# STM32U5xx register map
File version: 1.3
Registers are 32-bit, read-write, reset 0x0 unless marked. A register's access mark holds for its fields unless they carry their own. Offsets are from the block's base; [hi:lo] are bit positions; {n}, {i} and the like mark numbered series.

## ADC2
Base 0x46021000
Same registers: SEC_ADC2 0x56021000
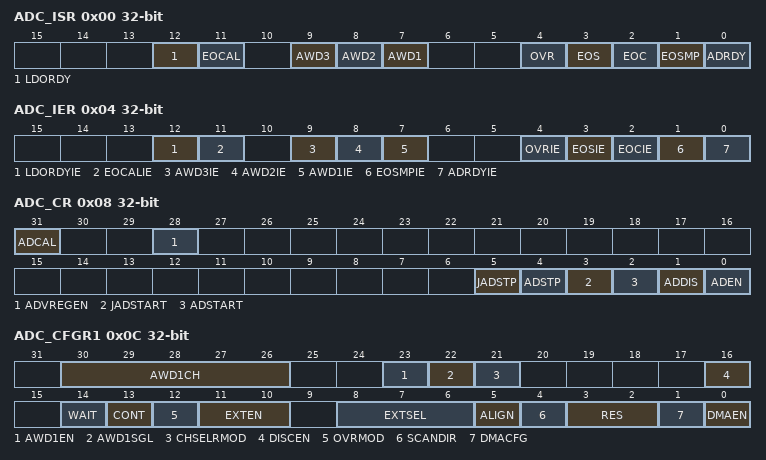
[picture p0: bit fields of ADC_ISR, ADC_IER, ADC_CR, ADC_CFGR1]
0x00 ADC_ISR — ADC interrupt and status register
  [12] LDORDY, [11] EOCAL, [9] AWD3, [8] AWD2, [7] AWD1, [4] OVR, [3] EOS, [2] EOC, [1] EOSMP, [0] ADRDY
0x04 ADC_IER — ADC interrupt enable register
  [12] LDORDYIE, [11] EOCALIE, [9] AWD3IE, [8] AWD2IE, [7] AWD1IE, [4] OVRIE, [3] EOSIE, [2] EOCIE, [1] EOSMPIE, [0] ADRDYIE
0x08 ADC_CR access per field — ADC control register
  [31] ADCAL ro, [28] ADVREGEN rw, [5] JADSTP ro, [4] ADSTP ro, [3] JADSTART ro, [2] ADSTART ro, [1] ADDIS ro, [0] ADEN ro
0x0C ADC_CFGR1 — ADC configuration register
  [30:26] AWD1CH, [23] AWD1EN, [22] AWD1SGL, [21] CHSELRMOD, [16] DISCEN, [14] WAIT, [13] CONT, [12] OVRMOD, [11:10] EXTEN, [8:6] EXTSEL, [5] ALIGN, [4] SCANDIR, [3:2] RES, [1] DMACFG, [0] DMAEN
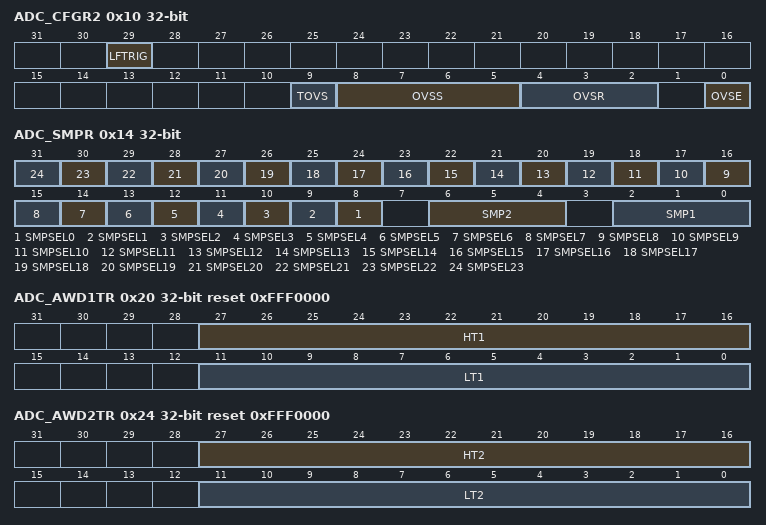
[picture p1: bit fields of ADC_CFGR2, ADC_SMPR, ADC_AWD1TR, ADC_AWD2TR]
0x10 ADC_CFGR2 — ADC configuration register 2
  [29] LFTRIG, [9] TOVS, [8:5] OVSS, [4:2] OVSR, [0] OVSE
0x14 ADC_SMPR — ADC sample time register
  [n+8] SMPSEL{n} (n=0..23), [6:4] SMP2, [2:0] SMP1
0x20 ADC_AWD1TR reset 0xFFF0000 — ADC watchdog threshold register
  [27:16] HT1, [11:0] LT1
0x24 ADC_AWD2TR reset 0xFFF0000 — ADC watchdog threshold register
  [27:16] HT2, [11:0] LT2
0x28 ADC_CHSELRMOD0 — ADC channel selection register [alternate]
  [23:0] CHSEL
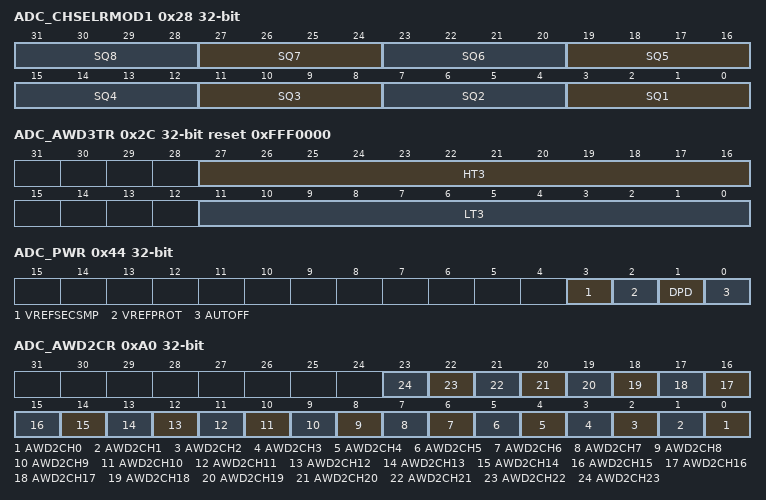
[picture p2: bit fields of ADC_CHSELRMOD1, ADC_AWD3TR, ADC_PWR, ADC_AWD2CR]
0x28 ADC_CHSELRMOD1 (alternate view of ADC_CHSELRMOD0) — ADC channel selection register [alternate]
  [4n-1:4n-4] SQ{n} (n=1..8)
0x2C ADC_AWD3TR reset 0xFFF0000 — ADC watchdog threshold register
  [27:16] HT3, [11:0] LT3
0x40 ADC_DR ro — ADC data register
  [15:0] DATA
0x44 ADC_PWR — ADC data register
  [3] VREFSECSMP, [2] VREFPROT, [1] DPD, [0] AUTOFF
0xA0 ADC_AWD2CR — ADC Analog Watchdog 2 Configuration register
  [n] AWD2CH{n} (n=0..23)
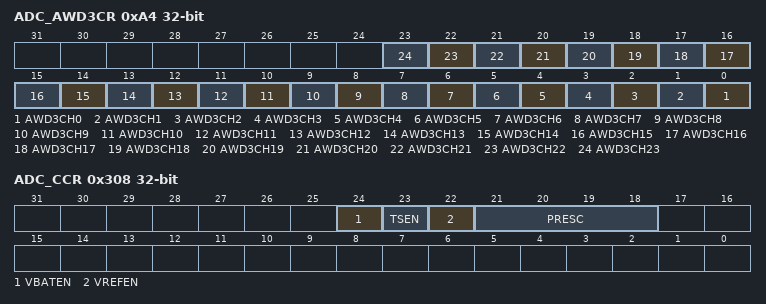
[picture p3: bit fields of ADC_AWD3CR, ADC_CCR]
0xA4 ADC_AWD3CR — ADC Analog Watchdog 3 Configuration register
  [n] AWD3CH{n} (n=0..23)
0xB4 ADC_CALFACT — ADC Calibration factor
  [6:0] CALFACT
0xD0 ADC_OR — ADC option register
  [0] CHN0SEL
0x308 ADC_CCR — ADC common configuration register
  [24] VBATEN, [23] TSEN, [22] VREFEN, [21:18] PRESC

## RNG — Random number generator
Base 0x420C0800
Same registers: SEC_RNG 0x520C0800
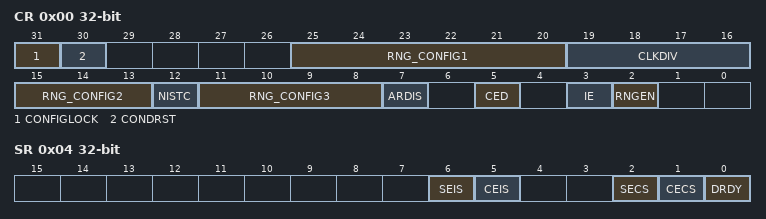
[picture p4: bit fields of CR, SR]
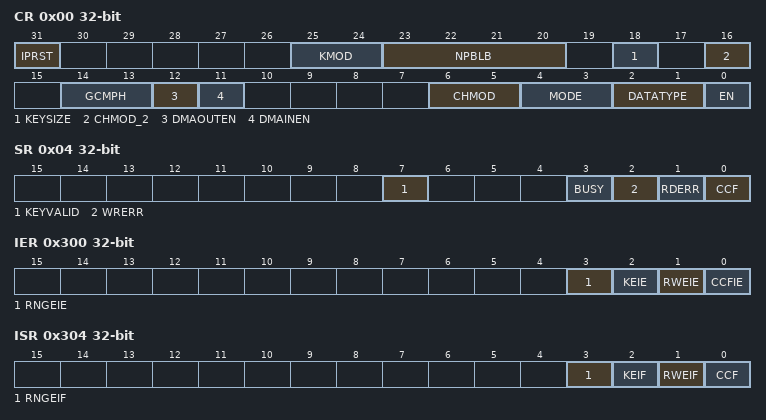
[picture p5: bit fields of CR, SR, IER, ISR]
0x00 CR — control register
  [31] CONFIGLOCK — RNG Config Lock
  [30] CONDRST — Conditioning soft reset
  [25:20] RNG_CONFIG1 — RNG configuration 1
  [19:16] CLKDIV — Clock divider factor
  [15:13] RNG_CONFIG2 — RNG configuration 2
  [12] NISTC — Non NIST compliant
  [11:8] RNG_CONFIG3 — RNG configuration 3
  [7] ARDIS — Auto reset disable
  [5] CED — Clock error detection
  [3] IE — Interrupt Enable
  [2] RNGEN — True random number generator enable
0x04 SR access per field — status register
  [6] SEIS rw — Seed error interrupt status
  [5] CEIS rw — Clock error interrupt status
  [2] SECS ro — Seed error current status
  [1] CECS ro — Clock error current status
  [0] DRDY ro — Data ready
0x08 DR ro — data register
  [31:0] RNDATA — Random data
0x10 HTCR reset 0x6274 — health test control register
  [31:0] HTCFG — health test configuration

## AES — Advanced encryption standard hardware accelerator
Base 0x420C0000
Same registers: SEC_AES 0x520C0000
0x00 CR — control register
  [31] IPRST
  [25:24] KMOD
  [23:20] NPBLB
  [18] KEYSIZE
  [16] CHMOD_2
  [14:13] GCMPH
  [12] DMAOUTEN — Enable DMA management of data output phase
  [11] DMAINEN — Enable DMA management of data input phase
  [6:5] CHMOD — AES chaining mode
  [4:3] MODE — AES operating mode
  [2:1] DATATYPE — Data type selection (for data in and data out to/from the cryptographic block)
  [0] EN — AES enable
0x04 SR ro — status register
  [7] KEYVALID — Key Valid flag
  [3] BUSY
  [2] WRERR — Write error flag
  [1] RDERR — Read error flag
  [0] CCF — Computation complete flag
0x08 DINR wo — data input register
  [31:0] DIN — Input data word
0x0C DOUTR ro — data output register
  [31:0] DOUT — Output data word
0x10 KEYR0 wo — key register 0
  [31:0] KEY — Cryptographic key, bits [31:0]
0x14 KEYR1 wo — key register 1
  [31:0] KEY — Cryptographic key, bits [63:32]
0x18 KEYR2 wo — key register 2
  [31:0] KEYR — Cryptographic key, bits [95:64]
0x1C KEYR3 wo — key register 3
  [31:0] AES_KEYR3 — Cryptographic key, bits [127:96]
{0x20+4i} IVR{i} (i=0..3) — initialization vector register {i}
  [31:0] IVI — Initialization vector input, bits [{32i+31}:{32i}]
{0x20+4i} KEYR{i} wo (i=4..7) — key register {i}
  [31:0] KEY — Cryptographic key, bits [{32i+31}:{32i}]
{0x40+4i} SUSP{i}R wo (i=0..7) — suspend registers
  [31:0] SUSP{i} — AES suspend
0x300 IER — interrupt enable register
  [3] RNGEIE — Key error interrupt flag
  [2] KEIE — Key error interrupt flag
  [1] RWEIE — Read or write error interrupt flag
  [0] CCFIE — Computation complete flag
0x304 ISR ro — interrupt status register
  [3] RNGEIF — Key error interrupt flag
  [2] KEIF — Key error interrupt flag
  [1] RWEIF — Read or write error interrupt flag
  [0] CCF — Computation complete flag
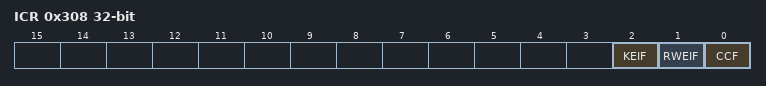
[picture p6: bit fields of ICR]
0x308 ICR wo — interrupt clear register
  [2] KEIF — Key error interrupt flag clear
  [1] RWEIF — Read or write error interrupt flag clear
  [0] CCF — Computation complete flag clear

## SAES — Secure AES coprocessor
Base 0x420C0C00
Same registers: SEC_SAES 0x520C0C00
Registers as AES (with AES read as SAES), without SUSP{n}R (n=0..7); these are added or differ:
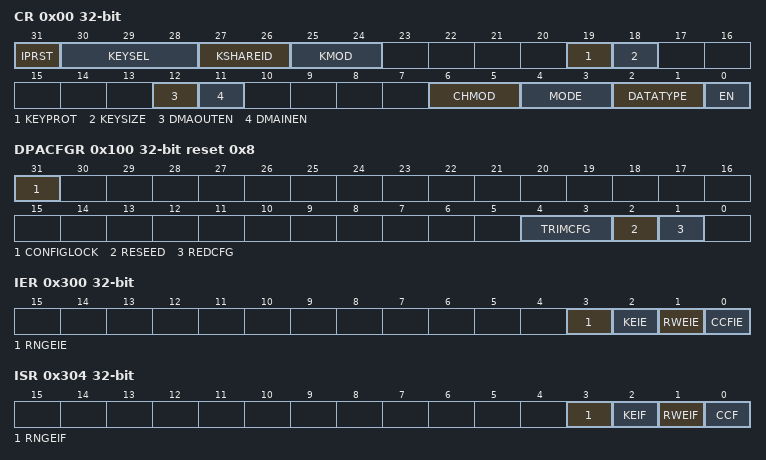
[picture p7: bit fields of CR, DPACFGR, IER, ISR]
0x00 CR — control register
  [31] IPRST
  [30:28] KEYSEL
  [27:26] KSHAREID
  [25:24] KMOD
  [19] KEYPROT
  [18] KEYSIZE
  [12] DMAOUTEN
  [11] DMAINEN
  [6:5] CHMOD
  [4:3] MODE
  [2:1] DATATYPE
  [0] EN — SAES enable
0x100 DPACFGR access per field reset 0x8 — configuration register
  [31] CONFIGLOCK ro, [4:3] TRIMCFG rw, [2] RESEED rw, [1] REDCFG rw
0x300 IER — interrupt enable register
  [3] RNGEIE
  [2] KEIE — Key error interrupt enable
  [1] RWEIE — Read or write error interrupt enable
  [0] CCFIE — Computation complete flag interrupt enable
0x304 ISR ro — interrupt status register
  [3] RNGEIF
  [2] KEIF — Key error interrupt flag
  [1] RWEIF — Read or write error interrupt flag
  [0] CCF — Computation complete flag
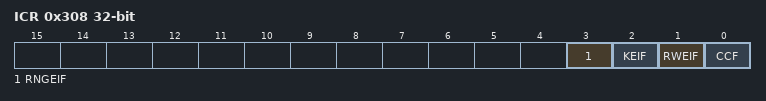
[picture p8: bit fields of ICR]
0x308 ICR wo — interrupt clear register
  [3] RNGEIF
  [2] KEIF — Key error interrupt flag clear
  [1] RWEIF — Read or write error interrupt flag clear
  [0] CCF — Computation complete flag clear
